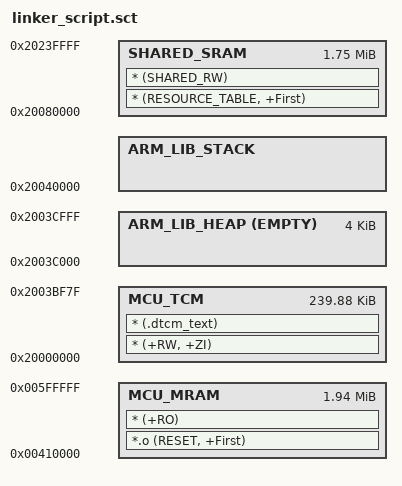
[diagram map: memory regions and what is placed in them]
;******************************************************************************
;
; Scatter file for Keil linker configuration.
;
;******************************************************************************
LR_1 0x00410000
{
    MCU_MRAM 0x00410000 0x001F0000
    {
        *.o (RESET, +First)
        * (+RO)
    }

    ;MCU_TCM dollar{rw_base} dollar{rw_size}
    ;The next line is a temporary workaround while FPGA doesn't have SSRAM. The above line is actually correct (replace dollar with the dollar sign)
    MCU_TCM 0x20000000 (0x0003C000-0x80)
    {
        * (+RW, +ZI)
        * (.dtcm_text)
    }

    ARM_LIB_HEAP  0x2003C000 EMPTY  0x00001000
    {   ; Reserve empty region for heap
    }

    ;SHARED_SRAM dollar{shared_base} dollar{shared_size}
    ;The next line is a temporary workaround while FPGA doesn't have SSRAM. The above line is actually correct (replace dollar with the dollar sign)
    SHARED_SRAM 0x20080000 0x001C0000
    {
        * (RESOURCE_TABLE, +First)
        * (SHARED_RW)
    }

    ARM_LIB_STACK 0x20040000 EMPTY - 0x00003000
    {   ; Reserve empty region for stack
    }


}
